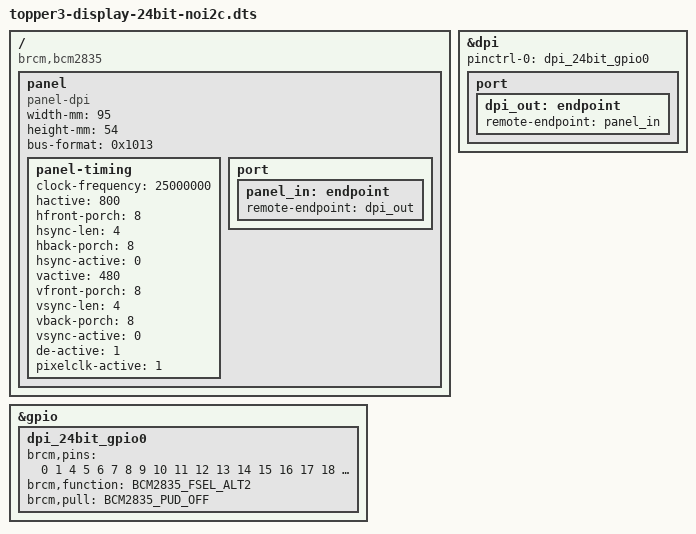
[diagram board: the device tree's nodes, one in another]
/dts-v1/;
/plugin/;

#include <dt-bindings/gpio/gpio.h>
#include <dt-bindings/pinctrl/bcm2835.h>

/ {
	compatible = "brcm,bcm2835";

	fragment@0 {
		target = <&dpi>;
		__overlay__ {
			status = "okay";
			pinctrl-names = "default";
			pinctrl-0 = <&dpi_24bit_gpio0>;
		};
	};

	fragment@1 {
		target = <&gpio>;
		__overlay__ {
			dpi_24bit_gpio0: dpi_24bit_gpio0 {
				brcm,pins = <0 1 4 5 6 7 8 9 10 11 12 13 14 15 16 17 18 19 20 21 22 23 24 25 26 27>;
				brcm,function = <BCM2835_FSEL_ALT2>;
				brcm,pull = <BCM2835_PUD_OFF>;
			};
		};
	};

	fragment@2 {
		target-path = "/";
		__overlay__ {
			panel: panel {
				compatible = "panel-dpi";
				width-mm = <95>;
				height-mm = <54>;
				bus-format = <0x1013>;

				panel-timing {
					clock-frequency = <25000000>;
					hactive = <800>;
					hfront-porch = <8>;
					hsync-len = <4>;
					hback-porch = <8>;
					hsync-active = <0>;
					vactive = <480>;
					vfront-porch = <8>;
					vsync-len = <4>;
					vback-porch = <8>;
					vsync-active = <0>;
					de-active = <1>;
					pixelclk-active = <1>;
				};

				port {
					panel_in: endpoint {
						remote-endpoint = <&dpi_out>;
					};
				};
			};
		};
	};

	fragment@3 {
		target = <&dpi>;
		__overlay__ {
			port {
				dpi_out: endpoint {
					remote-endpoint = <&panel_in>;
				};
			};
		};
	};
};
